# DDR16SS0_CTLPHY_WRAP_CTL_CFG_CTLCFG register map
Vendor: Texas Instruments
Registers are 32-bit, read-write, reset 0x0 unless marked. A register's access mark holds for its fields unless they carry their own. Offsets are as the file gives them; [hi:lo] are bit positions; lines under a group give offsets from that group; {n}, {i} and the like mark numbered series.

## DDR16SS0_CTLPHY_WRAP_CTL_CFG_CTLCFG (part 4 of 9)
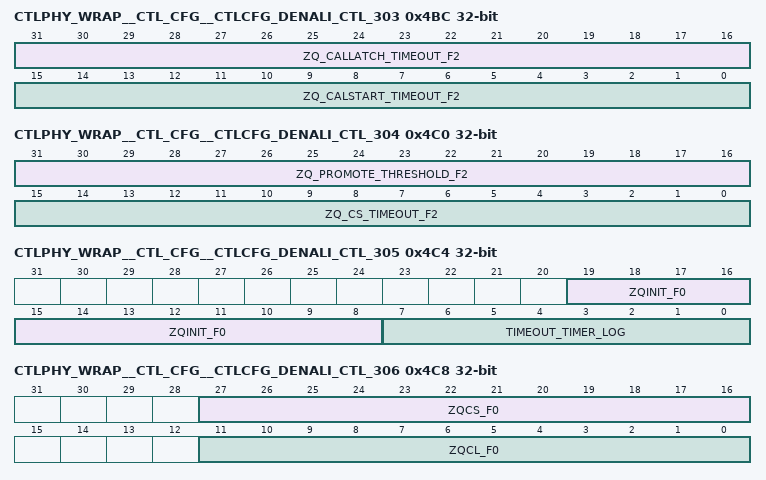
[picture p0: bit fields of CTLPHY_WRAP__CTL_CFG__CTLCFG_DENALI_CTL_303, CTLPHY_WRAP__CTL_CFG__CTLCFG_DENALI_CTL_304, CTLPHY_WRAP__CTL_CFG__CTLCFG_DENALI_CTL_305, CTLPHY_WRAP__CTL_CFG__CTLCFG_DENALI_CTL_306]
0x4BC CTLPHY_WRAP__CTL_CFG__CTLCFG_DENALI_CTL_303
  [31:16] ZQ_CALLATCH_TIMEOUT_F2 — ZQ LATCH number of long counts until the timeout is asserted. FC=2
  [15:0] ZQ_CALSTART_TIMEOUT_F2 — ZQ START number of long counts until the timeout is asserted. FC=2
0x4C0 CTLPHY_WRAP__CTL_CFG__CTLCFG_DENALI_CTL_304
  [31:16] ZQ_PROMOTE_THRESHOLD_F2 — ZQ SW promotion number of long counts until the high priority request is asserted. FC=2
  [15:0] ZQ_CS_TIMEOUT_F2 — ZQ CS number of long counts until the timeout is asserted. FC=2
0x4C4 CTLPHY_WRAP__CTL_CFG__CTLCFG_DENALI_CTL_305 access per field
  [19:8] ZQINIT_F0 rw — Number of cycles needed for a ZQINIT command. FC=0
  [7:0] TIMEOUT_TIMER_LOG ro — Reflects which timers experienced a timeout error [or had an uncleared error] when the timeout interrupt fired. Bit [0] correlates to a ZQ cal init, cs, cl, or reset FM timeout. Bit [1] correlates to the ZQ calstart FM timeout. Bit [2] correlates to the ZQ callatch FM timeout. Bit [3] correlates to the MRR temperature check FM timeout. Bit [4] correlates to the DQS oscillator FM timeout. Bit [5] correlates to the DFI update FM timeout. Bit [6] correlates to the low power interface wakeup timeout. Bit [7] correlates to the auto refresh max deficit timeout. READ-ONLY
0x4C8 CTLPHY_WRAP__CTL_CFG__CTLCFG_DENALI_CTL_306
  [27:16] ZQCS_F0 — Number of cycles needed for a ZQCS command. FC=0
  [11:0] ZQCL_F0 — Number of cycles needed for a ZQCL command. FC=0
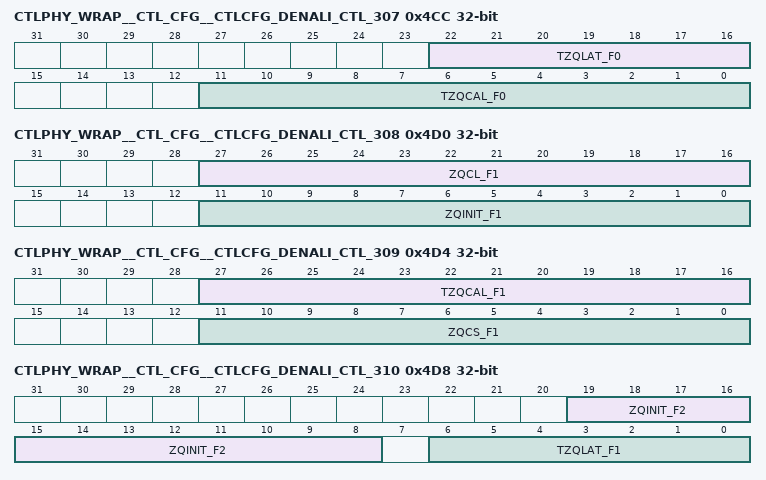
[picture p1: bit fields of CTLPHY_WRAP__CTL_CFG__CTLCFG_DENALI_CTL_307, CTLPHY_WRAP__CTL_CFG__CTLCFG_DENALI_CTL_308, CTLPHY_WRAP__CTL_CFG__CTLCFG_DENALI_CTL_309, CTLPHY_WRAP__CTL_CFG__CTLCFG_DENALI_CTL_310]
0x4CC CTLPHY_WRAP__CTL_CFG__CTLCFG_DENALI_CTL_307
  [22:16] TZQLAT_F0 — Holds the DRAM ZQLAT value in cycles. FC=0
  [11:0] TZQCAL_F0 — Holds the DRAM ZQCAL value in cycles. FC=0
0x4D0 CTLPHY_WRAP__CTL_CFG__CTLCFG_DENALI_CTL_308
  [27:16] ZQCL_F1 — Number of cycles needed for a ZQCL command. FC=1
  [11:0] ZQINIT_F1 — Number of cycles needed for a ZQINIT command. FC=1
0x4D4 CTLPHY_WRAP__CTL_CFG__CTLCFG_DENALI_CTL_309
  [27:16] TZQCAL_F1 — Holds the DRAM ZQCAL value in cycles. FC=1
  [11:0] ZQCS_F1 — Number of cycles needed for a ZQCS command. FC=1
0x4D8 CTLPHY_WRAP__CTL_CFG__CTLCFG_DENALI_CTL_310
  [19:8] ZQINIT_F2 — Number of cycles needed for a ZQINIT command. FC=2
  [6:0] TZQLAT_F1 — Holds the DRAM ZQLAT value in cycles. FC=1
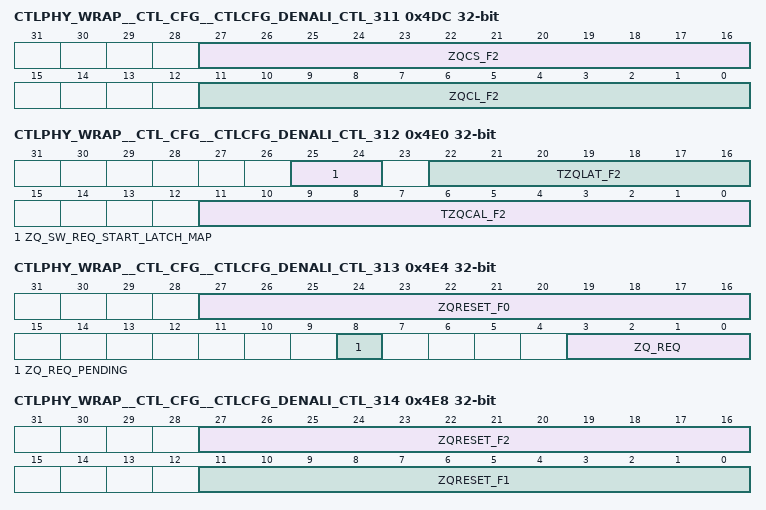
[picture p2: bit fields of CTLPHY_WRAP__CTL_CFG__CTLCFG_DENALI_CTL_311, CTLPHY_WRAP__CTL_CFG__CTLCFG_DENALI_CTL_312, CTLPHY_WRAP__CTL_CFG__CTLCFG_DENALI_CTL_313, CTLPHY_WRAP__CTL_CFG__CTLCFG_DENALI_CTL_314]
0x4DC CTLPHY_WRAP__CTL_CFG__CTLCFG_DENALI_CTL_311
  [27:16] ZQCS_F2 — Number of cycles needed for a ZQCS command. FC=2
  [11:0] ZQCL_F2 — Number of cycles needed for a ZQCL command. FC=2
0x4E0 CTLPHY_WRAP__CTL_CFG__CTLCFG_DENALI_CTL_312
  [25:24] ZQ_SW_REQ_START_LATCH_MAP — Specifies which chip selects will simultaneously receive a ZQ start or latch command once the ZQ_REQ parameter is written with a ZQ Start or ZQ Latch command.
  [22:16] TZQLAT_F2 — Holds the DRAM ZQLAT value in cycles. FC=2
  [11:0] TZQCAL_F2 — Holds the DRAM ZQCAL value in cycles. FC=2
0x4E4 CTLPHY_WRAP__CTL_CFG__CTLCFG_DENALI_CTL_313 access per field
  [27:16] ZQRESET_F0 rw — Number of cycles needed for a ZQRESET command. FC=0
  [8] ZQ_REQ_PENDING ro — Indicates that a ZQ command is currently in progress or waiting to run. Value of 1 indicates command in progress or waiting to run. When this is asserted, no writes to ZQ_REQ should occur. READ-ONLY
  [3:0] ZQ_REQ wo — User request to initiate a ZQ calibration. Program to 3 for ZQ Start, program to 4 for ZQ Initialization [ZQINIT], program to 5 for ZQ Latch, or program to 8 for ZQ Reset. Clearing to 0 will not trigger any ZQ command. This parameter should only be written when the ZQ_REQ_PENDING parameter is cleared to 0. WRITE-ONLY
0x4E8 CTLPHY_WRAP__CTL_CFG__CTLCFG_DENALI_CTL_314
  [27:16] ZQRESET_F2 — Number of cycles needed for a ZQRESET command. FC=2
  [11:0] ZQRESET_F1 — Number of cycles needed for a ZQRESET command. FC=1
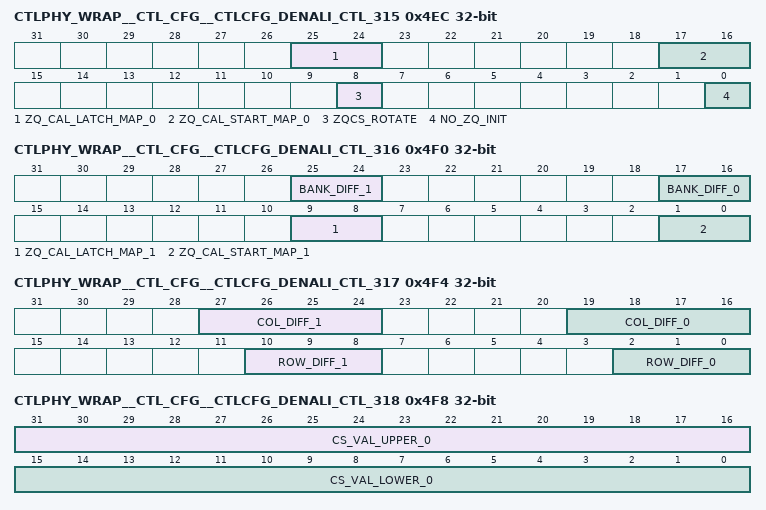
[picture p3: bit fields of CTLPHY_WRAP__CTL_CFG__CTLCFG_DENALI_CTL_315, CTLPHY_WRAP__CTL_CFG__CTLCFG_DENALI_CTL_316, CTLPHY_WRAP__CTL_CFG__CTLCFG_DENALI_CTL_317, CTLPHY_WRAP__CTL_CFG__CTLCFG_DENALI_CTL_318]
0x4EC CTLPHY_WRAP__CTL_CFG__CTLCFG_DENALI_CTL_315
  [25:24] ZQ_CAL_LATCH_MAP_0 — Defines which chip select[s] will receive ZQ calibration latch commands simultaneously on iteration 0 of the ZQ LATCH initialization and periodic command sequences. Clear to all zeros for no ZQ LATCH commands. CS=0
  [17:16] ZQ_CAL_START_MAP_0 — Defines which chip select[s] will receive ZQ calibration start commands simultaneously on iteration 0 of the ZQ START initialization and periodic command sequences. Clear to all zeros for no ZQ START commands. CS=0
  [8] ZQCS_ROTATE — For memories that perform ZQ short commands [ZQCS], selects whether a ZQCS command will calibrate just one chip select or all chip selects. When rotation is off, all chip selects will be calibrated, requiring a longer time frame, but ZQ calibration will need to be performed less frequently. Set to 1 for rotating CS. For ZQ start/latch memories, this parameter is ignored.
  [0] NO_ZQ_INIT — Disable ZQ operations during initialization. Set to 1 to disable.
0x4F0 CTLPHY_WRAP__CTL_CFG__CTLCFG_DENALI_CTL_316
  [25:24] BANK_DIFF_1 — Encoded number of banks on the DRAM[s].
  [17:16] BANK_DIFF_0 — Encoded number of banks on the DRAM[s].
  [9:8] ZQ_CAL_LATCH_MAP_1 — Defines which chip select[s] will receive ZQ calibration latch commands simultaneously on iteration 1 of the ZQ LATCH initialization and periodic command sequences. Clear to all zeros for no ZQ LATCH commands. CS=1
  [1:0] ZQ_CAL_START_MAP_1 — Defines which chip select[s] will receive ZQ calibration start commands simultaneously on iteration 1 of the ZQ START initialization and periodic command sequences. Clear to all zeros for no ZQ START commands. CS=1
0x4F4 CTLPHY_WRAP__CTL_CFG__CTLCFG_DENALI_CTL_317
  [27:24] COL_DIFF_1 — Difference between number of column pins available and number being used.
  [19:16] COL_DIFF_0 — Difference between number of column pins available and number being used.
  [10:8] ROW_DIFF_1 — Difference between number of address pins available and number being used.
  [2:0] ROW_DIFF_0 — Difference between number of address pins available and number being used.
0x4F8 CTLPHY_WRAP__CTL_CFG__CTLCFG_DENALI_CTL_318
  [31:16] CS_VAL_UPPER_0 — Upper bound address for chip select 0.
  [15:0] CS_VAL_LOWER_0 — Lower bound address for chip select 0.
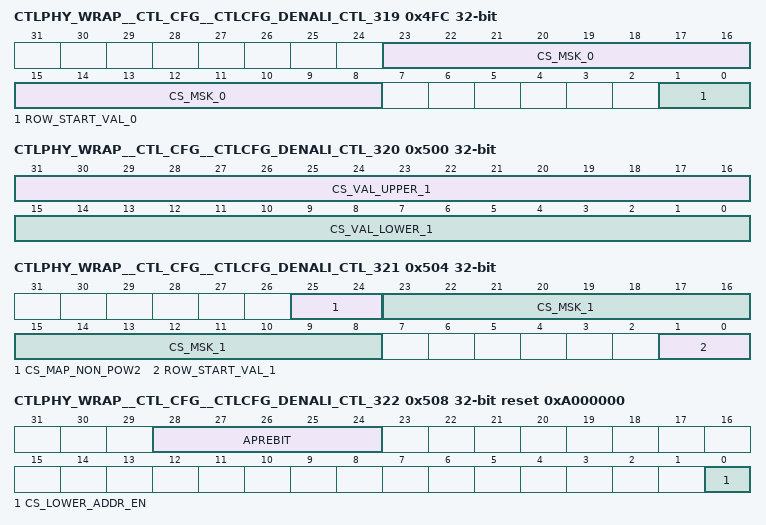
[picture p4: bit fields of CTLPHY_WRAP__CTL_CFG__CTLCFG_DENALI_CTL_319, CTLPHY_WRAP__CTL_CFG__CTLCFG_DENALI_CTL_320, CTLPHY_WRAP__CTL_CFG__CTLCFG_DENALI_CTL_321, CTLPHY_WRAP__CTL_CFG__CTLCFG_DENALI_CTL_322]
0x4FC CTLPHY_WRAP__CTL_CFG__CTLCFG_DENALI_CTL_319
  [23:8] CS_MSK_0 — Mask applied to the address decode for chip select 0.
  [1:0] ROW_START_VAL_0 — Row start value for chip select 0.
0x500 CTLPHY_WRAP__CTL_CFG__CTLCFG_DENALI_CTL_320
  [31:16] CS_VAL_UPPER_1 — Upper bound address for chip select 1.
  [15:0] CS_VAL_LOWER_1 — Lower bound address for chip select 1.
0x504 CTLPHY_WRAP__CTL_CFG__CTLCFG_DENALI_CTL_321
  [25:24] CS_MAP_NON_POW2 — Defines which chip selects are non-power-of-2 memory sizes.
  [23:8] CS_MSK_1 — Mask applied to the address decode for chip select 1.
  [1:0] ROW_START_VAL_1 — Row start value for chip select 1.
0x508 CTLPHY_WRAP__CTL_CFG__CTLCFG_DENALI_CTL_322 reset 0xA000000
  [28:24] APREBIT — Location of the auto pre-charge bit in the DRAM address.
  [0] CS_LOWER_ADDR_EN — Enables moving the CS field to lower in the address map. When set to 1, the memory address map will be changed to ROW__CS__BANK. Please refer to the limitations before setting this bit.
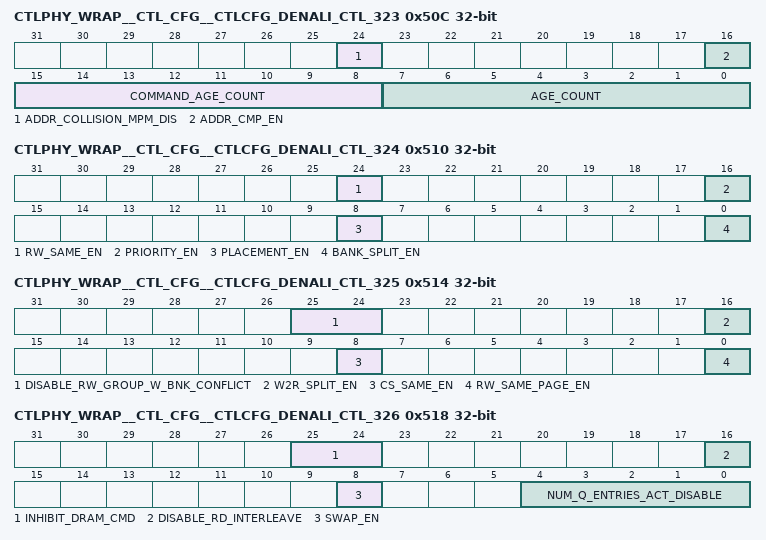
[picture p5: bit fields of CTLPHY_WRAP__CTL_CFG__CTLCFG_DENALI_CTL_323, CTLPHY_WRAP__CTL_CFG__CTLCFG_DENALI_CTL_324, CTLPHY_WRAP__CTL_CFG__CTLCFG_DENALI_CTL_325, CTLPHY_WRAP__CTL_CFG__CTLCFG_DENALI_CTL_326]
0x50C CTLPHY_WRAP__CTL_CFG__CTLCFG_DENALI_CTL_323
  [24] ADDR_COLLISION_MPM_DIS — Disable address collision detection extension using micro page mask for command queue placement and selection. Set to 1 to disable.
  [16] ADDR_CMP_EN — Enable address collision detection as a rule for command queue placement. Set to 1 to enable.
  [15:8] COMMAND_AGE_COUNT — Initial value of individual command aging counters for command aging.
  [7:0] AGE_COUNT — Initial value of master aging-rate counter for command aging.
0x510 CTLPHY_WRAP__CTL_CFG__CTLCFG_DENALI_CTL_324
  [24] RW_SAME_EN — Enable read/write grouping as a rule for command queue placement. Set to 1 to enable.
  [16] PRIORITY_EN — Enable priority as a rule for command queue placement. Set to 1 to enable.
  [8] PLACEMENT_EN — Enable placement logic for command queue. Set to 1 to enable.
  [0] BANK_SPLIT_EN — Enable bank splitting as a rule for command queue placement. Set to 1 to enable.
0x514 CTLPHY_WRAP__CTL_CFG__CTLCFG_DENALI_CTL_325
  [25:24] DISABLE_RW_GROUP_W_BNK_CONFLICT — Disables placement to read/write group when grouping creates a bank collision. Bit [0] controls placement next to bank conflict command and bit [1] controls placement 2 away from bank conflict command. Set each bit to 1 to disable.
  [16] W2R_SPLIT_EN — Enable splitting of commands to the same chip select from a write to a read command as a rule for command queue placement.
  [8] CS_SAME_EN — Enable chip select grouping when read/write grouping as a rule for command queue placement. This is only valid when the RW_SAME_EN parameter is set. Set to 1 to enable.
  [0] RW_SAME_PAGE_EN — Enable page grouping when read/write grouping as a rule for command queue placement. This is only valid when the RW_SAME_EN parameter is set. Set to 1 to enable.
0x518 CTLPHY_WRAP__CTL_CFG__CTLCFG_DENALI_CTL_326
  [25:24] INHIBIT_DRAM_CMD — Inhibit command types from being executed from the command queue. Clear to 0 to enable any command, program to 1 to inhibit read/write and bank commands, program to 2 to inhibit MRR and peripheral MRR commands, or program to 3 to inhibit MRR and read/write commands.
  [16] DISABLE_RD_INTERLEAVE — Disable read data interleaving for commands from the same port, regardless of the requestor ID.
  [8] SWAP_EN — Enable command swapping logic in execution unit. Set to 1 to enable.
  [4:0] NUM_Q_ENTRIES_ACT_DISABLE — Number of queue entries in which ACT requests will be disabled. Programming to X will disable ACT requests from the X entries lowest in the command queue.
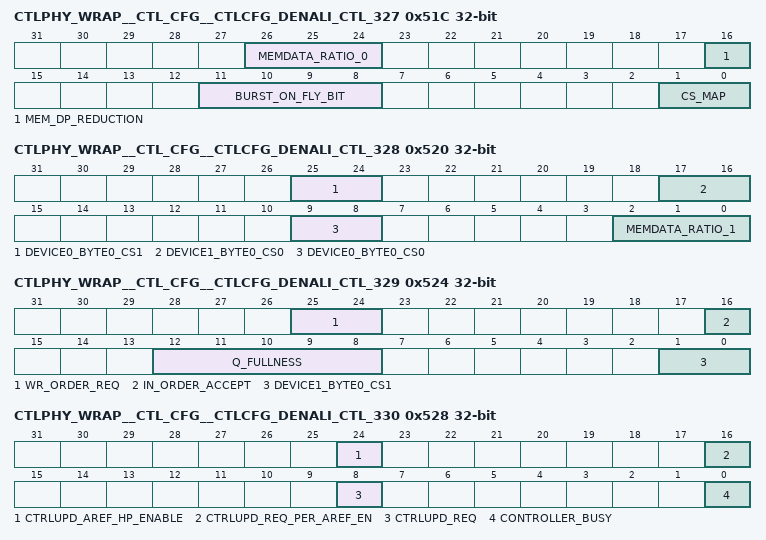
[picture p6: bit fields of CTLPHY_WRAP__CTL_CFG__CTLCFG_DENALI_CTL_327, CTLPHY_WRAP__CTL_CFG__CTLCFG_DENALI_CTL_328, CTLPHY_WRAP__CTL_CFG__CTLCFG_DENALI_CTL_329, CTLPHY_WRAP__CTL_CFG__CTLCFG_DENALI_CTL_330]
0x51C CTLPHY_WRAP__CTL_CFG__CTLCFG_DENALI_CTL_327
  [26:24] MEMDATA_RATIO_0 — Defines the ratio of the DRAM device size on chip select 0 to the memory data width. Program with the log2 ratio of the memory data width to the device data width. CS=0
  [16] MEM_DP_REDUCTION — Enable the half datapath feature of the controller. Set to 1 to enable.
  [11:8] BURST_ON_FLY_BIT — Identifies the burst-on-fly bit in the memory mode registers.
  [1:0] CS_MAP — Defines which chip selects are active.
0x520 CTLPHY_WRAP__CTL_CFG__CTLCFG_DENALI_CTL_328
  [25:24] DEVICE0_BYTE0_CS1 — Defines the byte location of byte0 in the memory datapath for device 0 on chip 1. Used for MRRs to identify where data will be returned. DEV=0
  [17:16] DEVICE1_BYTE0_CS0 — Defines the byte location of byte0 in the memory datapath for device 1 on chip 0. Used for MRRs to identify where data will be returned. DEV=1
  [9:8] DEVICE0_BYTE0_CS0 — Defines the byte location of byte0 in the memory datapath for device 0 on chip 0. Used for MRRs to identify where data will be returned. DEV=0
  [2:0] MEMDATA_RATIO_1 — Defines the ratio of the DRAM device size on chip select 1 to the memory data width. Program with the log2 ratio of the memory data width to the device data width. CS=1
0x524 CTLPHY_WRAP__CTL_CFG__CTLCFG_DENALI_CTL_329
  [25:24] WR_ORDER_REQ — Determines if the controller can re-order write commands from the same source ID and/or the same port. Bit [0] controls source ID usage and bit [1] controls port ID usage. Set each bit to 1 to enable usage in placement logic.
  [16] IN_ORDER_ACCEPT — Forces the controller to accept commands in the order in which they are placed in the command queue.
  [12:8] Q_FULLNESS — Quantity that determines when the command queue almost full signal will assert [q_almost_full]. When cleared to 0, the q_almost_full signal will be driven to 0 irrespective of number of entries in the command queue.
  [1:0] DEVICE1_BYTE0_CS1 — Defines the byte location of byte0 in the memory datapath for device 1 on chip 1. Used for MRRs to identify where data will be returned. DEV=1
0x528 CTLPHY_WRAP__CTL_CFG__CTLCFG_DENALI_CTL_330 access per field
  [24] CTRLUPD_AREF_HP_ENABLE rw — Enable an automatic controller-initiated update [dfi_ctrlupd_req] after every high priority refresh when executing as a subtask request. Set to 1 to enable.
  [16] CTRLUPD_REQ_PER_AREF_EN rw — Enable an automatic controller-initiated update [dfi_ctrlupd_req] after every refresh. Set to 1 to enable.
  [8] CTRLUPD_REQ wo — Assert the DFI controller-initiated update request signal dfi_ctrlupd_req. Set to 1 to trigger. WRITE-ONLY
  [0] CONTROLLER_BUSY ro — Indicator that the controller is processing a command. Evaluates all ports for outstanding transactions. Value of 1 indicates controller busy. READ-ONLY
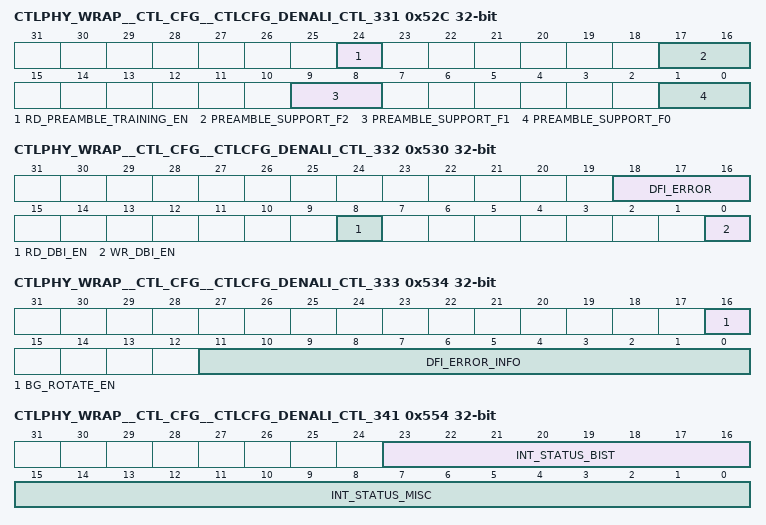
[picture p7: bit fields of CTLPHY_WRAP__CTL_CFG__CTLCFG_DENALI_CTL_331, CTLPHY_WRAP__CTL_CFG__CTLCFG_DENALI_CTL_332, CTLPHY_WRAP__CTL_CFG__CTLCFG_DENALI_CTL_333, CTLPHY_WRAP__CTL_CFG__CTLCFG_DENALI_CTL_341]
0x52C CTLPHY_WRAP__CTL_CFG__CTLCFG_DENALI_CTL_331
  [24] RD_PREAMBLE_TRAINING_EN — Enable read preamble training during gate training. Set to 1 to enable.
  [17:16] PREAMBLE_SUPPORT_F2 — Selection the preamble for read and write burst transfers. FC=2
  [9:8] PREAMBLE_SUPPORT_F1 — Selection the preamble for read and write burst transfers. FC=1
  [1:0] PREAMBLE_SUPPORT_F0 — Selection the preamble for read and write burst transfers. FC=0
0x530 CTLPHY_WRAP__CTL_CFG__CTLCFG_DENALI_CTL_332 access per field
  [18:16] DFI_ERROR ro — Indicates that the DFI error flag has been asserted. READ-ONLY
  [8] RD_DBI_EN rw — Enables controller support of DRAM DBI feature for read data with DDR4 devices. Set to 1 to enable.
  [0] WR_DBI_EN rw — Enables controller support of DRAM DBI feature for write data with DDR4 devices. Set to 1 to enable.
0x534 CTLPHY_WRAP__CTL_CFG__CTLCFG_DENALI_CTL_333 access per field
  [16] BG_ROTATE_EN rw — Enable bank group rotation. Set to 1 to enable.
  [11:0] DFI_ERROR_INFO ro — Holds the encoded DFI error type associated with the DFI_ERROR parameter assertion. READ-ONLY
0x538 CTLPHY_WRAP__CTL_CFG__CTLCFG_DENALI_CTL_334 ro
  [31:0] INT_STATUS_MASTER — Master status reporting register for interrupt status groups. READ-ONLY
0x53C CTLPHY_WRAP__CTL_CFG__CTLCFG_DENALI_CTL_335
  [31:0] INT_MASK_MASTER — Master mask register for interrupt status groups. WRITE-ONLY
0x540 CTLPHY_WRAP__CTL_CFG__CTLCFG_DENALI_CTL_336 ro
  [31:0] INT_STATUS_TIMEOUT — Status of interrupts in the controller related to Timeout monitors. READ-ONLY
0x544 CTLPHY_WRAP__CTL_CFG__CTLCFG_DENALI_CTL_337 ro
  [31:16] INT_STATUS_LOWPOWER — Status of interrupts in the controller related to Low Power. READ-ONLY
0x548 CTLPHY_WRAP__CTL_CFG__CTLCFG_DENALI_CTL_338 access not given reset not defined
0x54C CTLPHY_WRAP__CTL_CFG__CTLCFG_DENALI_CTL_339 ro
  [31:0] INT_STATUS_TRAINING — Status of interrupts in the controller related to Training/Calibration. READ-ONLY
0x550 CTLPHY_WRAP__CTL_CFG__CTLCFG_DENALI_CTL_340 ro
  [31:0] INT_STATUS_USERIF — Status of interrupts in the controller related to ASIC to Controller Interface. READ-ONLY
0x554 CTLPHY_WRAP__CTL_CFG__CTLCFG_DENALI_CTL_341 ro
  [23:16] INT_STATUS_BIST — Status of interrupts in the controller related to BIST. READ-ONLY
  [15:0] INT_STATUS_MISC — Status of interrupts in the controller related to Miscellaneous features. READ-ONLY
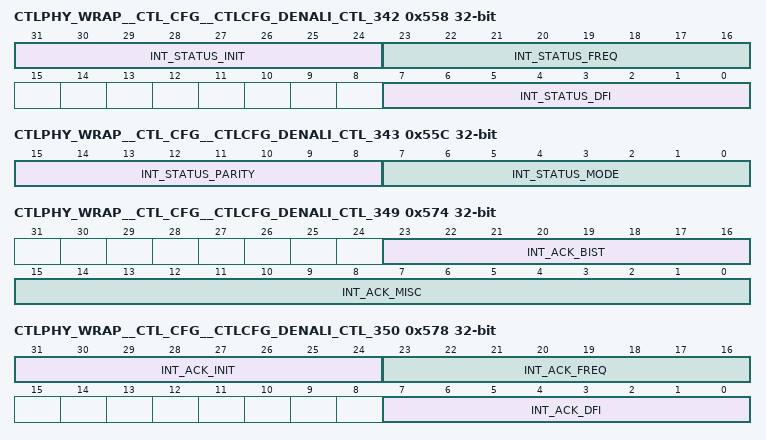
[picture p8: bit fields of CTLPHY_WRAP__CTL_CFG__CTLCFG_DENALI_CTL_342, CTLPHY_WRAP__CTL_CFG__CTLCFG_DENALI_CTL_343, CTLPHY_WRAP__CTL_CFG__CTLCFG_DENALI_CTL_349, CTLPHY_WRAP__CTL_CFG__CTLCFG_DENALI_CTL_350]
0x558 CTLPHY_WRAP__CTL_CFG__CTLCFG_DENALI_CTL_342 ro
  [31:24] INT_STATUS_INIT — Status of interrupts in the controller related to Initialization. READ-ONLY
  [23:16] INT_STATUS_FREQ — Status of interrupts in the controller related to Frequency Scaling. READ-ONLY
  [7:0] INT_STATUS_DFI — Status of interrupts in the controller related to DFI. READ-ONLY
0x55C CTLPHY_WRAP__CTL_CFG__CTLCFG_DENALI_CTL_343 ro
  [15:8] INT_STATUS_PARITY — Status of interrupts in the controller related to Parity. READ-ONLY
  [7:0] INT_STATUS_MODE — Status of interrupts in the controller related to Memory Mode Settings. READ-ONLY
0x560 CTLPHY_WRAP__CTL_CFG__CTLCFG_DENALI_CTL_344 wo
  [31:0] INT_ACK_TIMEOUT — Clear status of the INT_STATUS_TIMEOUT parameter. WRITE-ONLY
0x564 CTLPHY_WRAP__CTL_CFG__CTLCFG_DENALI_CTL_345 wo
  [31:16] INT_ACK_LOWPOWER — Clear status of the INT_STATUS_LOWPOWER parameter. WRITE-ONLY
0x568 CTLPHY_WRAP__CTL_CFG__CTLCFG_DENALI_CTL_346 access not given reset not defined
0x56C CTLPHY_WRAP__CTL_CFG__CTLCFG_DENALI_CTL_347 wo
  [31:0] INT_ACK_TRAINING — Clear status of the INT_STATUS_TRAINING parameter. WRITE-ONLY
0x570 CTLPHY_WRAP__CTL_CFG__CTLCFG_DENALI_CTL_348 wo
  [31:0] INT_ACK_USERIF — Clear status of the INT_STATUS_USERIF parameter. WRITE-ONLY
0x574 CTLPHY_WRAP__CTL_CFG__CTLCFG_DENALI_CTL_349 wo
  [23:16] INT_ACK_BIST — Clear status of the INT_STATUS_BIST parameter. WRITE-ONLY
  [15:0] INT_ACK_MISC — Clear status of the INT_STATUS_MISC parameter. WRITE-ONLY
0x578 CTLPHY_WRAP__CTL_CFG__CTLCFG_DENALI_CTL_350 wo
  [31:24] INT_ACK_INIT — Clear status of the INT_STATUS_INIT parameter. WRITE-ONLY
  [23:16] INT_ACK_FREQ — Clear status of the INT_STATUS_FREQ parameter. WRITE-ONLY
  [7:0] INT_ACK_DFI — Clear status of the INT_STATUS_DFI parameter. WRITE-ONLY
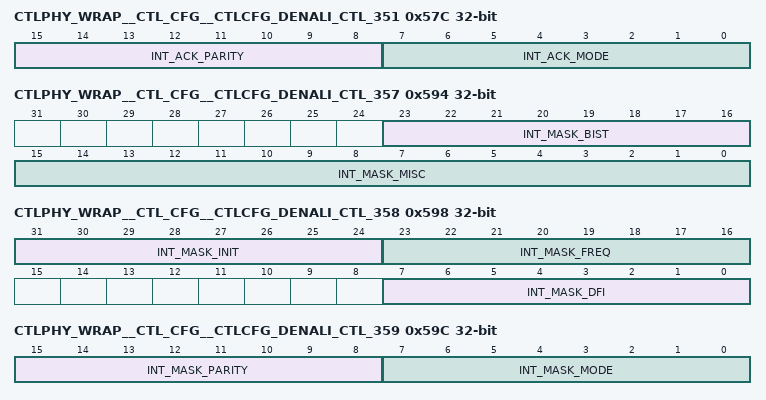
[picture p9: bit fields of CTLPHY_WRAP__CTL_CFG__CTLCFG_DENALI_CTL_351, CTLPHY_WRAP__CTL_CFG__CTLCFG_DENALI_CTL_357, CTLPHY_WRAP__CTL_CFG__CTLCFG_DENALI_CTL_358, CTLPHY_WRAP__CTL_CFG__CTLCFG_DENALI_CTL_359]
0x57C CTLPHY_WRAP__CTL_CFG__CTLCFG_DENALI_CTL_351 wo
  [15:8] INT_ACK_PARITY — Clear status of the INT_STATUS_PARITY parameter. WRITE-ONLY
  [7:0] INT_ACK_MODE — Clear status of the INT_STATUS_MODE parameter. WRITE-ONLY
0x580 CTLPHY_WRAP__CTL_CFG__CTLCFG_DENALI_CTL_352
  [31:0] INT_MASK_TIMEOUT — Mask for the controller_int signal from the INT_MASK_TIMEOUT parameter
0x584 CTLPHY_WRAP__CTL_CFG__CTLCFG_DENALI_CTL_353
  [31:16] INT_MASK_LOWPOWER — Mask for the controller_int signal from the INT_MASK_LOWPOWER parameter
0x588 CTLPHY_WRAP__CTL_CFG__CTLCFG_DENALI_CTL_354 access not given reset not defined
0x58C CTLPHY_WRAP__CTL_CFG__CTLCFG_DENALI_CTL_355
  [31:0] INT_MASK_TRAINING — Mask for the controller_int signal from the INT_MASK_TRAINING parameter
0x590 CTLPHY_WRAP__CTL_CFG__CTLCFG_DENALI_CTL_356
  [31:0] INT_MASK_USERIF — Mask for the controller_int signal from the INT_MASK_USERIF parameter
0x594 CTLPHY_WRAP__CTL_CFG__CTLCFG_DENALI_CTL_357
  [23:16] INT_MASK_BIST — Mask for the controller_int signal from the INT_MASK_BIST parameter
  [15:0] INT_MASK_MISC — Mask for the controller_int signal from the INT_MASK_MISC parameter
0x598 CTLPHY_WRAP__CTL_CFG__CTLCFG_DENALI_CTL_358
  [31:24] INT_MASK_INIT — Mask for the controller_int signal from the INT_MASK_INIT parameter
  [23:16] INT_MASK_FREQ — Mask for the controller_int signal from the INT_MASK_FREQ parameter
  [7:0] INT_MASK_DFI — Mask for the controller_int signal from the INT_MASK_DFI parameter
0x59C CTLPHY_WRAP__CTL_CFG__CTLCFG_DENALI_CTL_359
  [15:8] INT_MASK_PARITY — Mask for the controller_int signal from the INT_MASK_PARITY parameter
  [7:0] INT_MASK_MODE — Mask for the controller_int signal from the INT_MASK_MODE parameter
0x5A0 CTLPHY_WRAP__CTL_CFG__CTLCFG_DENALI_CTL_360 ro
  [31:0] OUT_OF_RANGE_ADDR_0 — Address of command that caused an out-of-range interrupt. READ-ONLY
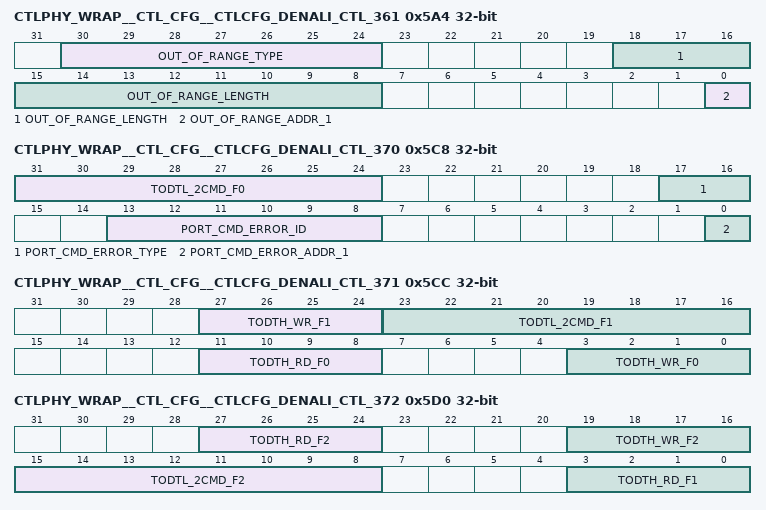
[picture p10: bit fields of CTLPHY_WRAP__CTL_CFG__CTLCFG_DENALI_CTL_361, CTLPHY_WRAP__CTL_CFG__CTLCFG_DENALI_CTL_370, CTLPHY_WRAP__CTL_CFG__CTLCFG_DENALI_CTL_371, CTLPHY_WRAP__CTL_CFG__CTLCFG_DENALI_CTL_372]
0x5A4 CTLPHY_WRAP__CTL_CFG__CTLCFG_DENALI_CTL_361 ro
  [30:24] OUT_OF_RANGE_TYPE — Type of command that caused an out-of-range interrupt. READ-ONLY
  [18:8] OUT_OF_RANGE_LENGTH — Length of command that caused an out-of-range interrupt. READ-ONLY
  [0] OUT_OF_RANGE_ADDR_1 — Address of command that caused an out-of-range interrupt. READ-ONLY
0x5A8 CTLPHY_WRAP__CTL_CFG__CTLCFG_DENALI_CTL_362 ro
  [5:0] OUT_OF_RANGE_SOURCE_ID — Source ID of command that caused an out-of-range interrupt. READ-ONLY
0x5AC CTLPHY_WRAP__CTL_CFG__CTLCFG_DENALI_CTL_363 ro
  [31:0] BIST_EXP_DATA_0 — Expected data on BIST error. READ-ONLY
0x5B0 CTLPHY_WRAP__CTL_CFG__CTLCFG_DENALI_CTL_364 ro
  [31:0] BIST_EXP_DATA_1 — Expected data on BIST error. READ-ONLY
0x5B4 CTLPHY_WRAP__CTL_CFG__CTLCFG_DENALI_CTL_365 ro
  [31:0] BIST_FAIL_DATA_0 — Actual data on BIST error. READ-ONLY
0x5B8 CTLPHY_WRAP__CTL_CFG__CTLCFG_DENALI_CTL_366 ro
  [31:0] BIST_FAIL_DATA_1 — Actual data on BIST error. READ-ONLY
0x5BC CTLPHY_WRAP__CTL_CFG__CTLCFG_DENALI_CTL_367 ro
  [31:0] BIST_FAIL_ADDR_0 — Address of BIST error. READ-ONLY
0x5C0 CTLPHY_WRAP__CTL_CFG__CTLCFG_DENALI_CTL_368 ro
  [0] BIST_FAIL_ADDR_1 — Address of BIST error. READ-ONLY
0x5C4 CTLPHY_WRAP__CTL_CFG__CTLCFG_DENALI_CTL_369 ro
  [31:0] PORT_CMD_ERROR_ADDR_0 — Address of command that caused the PORT command error. READ-ONLY
0x5C8 CTLPHY_WRAP__CTL_CFG__CTLCFG_DENALI_CTL_370 access per field
  [31:24] TODTL_2CMD_F0 rw — Defines the DRAM delay from an ODT de-assertion to the next non-write, non-read command. FC=0
  [17:16] PORT_CMD_ERROR_TYPE ro — Type of error and access type that caused the PORT command error. READ-ONLY
  [13:8] PORT_CMD_ERROR_ID ro — Source ID of command that caused the PORT command error. READ-ONLY
  [0] PORT_CMD_ERROR_ADDR_1 ro — Address of command that caused the PORT command error. READ-ONLY
0x5CC CTLPHY_WRAP__CTL_CFG__CTLCFG_DENALI_CTL_371
  [27:24] TODTH_WR_F1 — Defines the DRAM minimum ODT high time after an ODT assertion for a write command. FC=1
  [23:16] TODTL_2CMD_F1 — Defines the DRAM delay from an ODT de-assertion to the next non-write, non-read command. FC=1
  [11:8] TODTH_RD_F0 — Defines the DRAM minimum ODT high time after an ODT assertion for a read command. FC=0
  [3:0] TODTH_WR_F0 — Defines the DRAM minimum ODT high time after an ODT assertion for a write command. FC=0
0x5D0 CTLPHY_WRAP__CTL_CFG__CTLCFG_DENALI_CTL_372
  [27:24] TODTH_RD_F2 — Defines the DRAM minimum ODT high time after an ODT assertion for a read command. FC=2
  [19:16] TODTH_WR_F2 — Defines the DRAM minimum ODT high time after an ODT assertion for a write command. FC=2
  [15:8] TODTL_2CMD_F2 — Defines the DRAM delay from an ODT de-assertion to the next non-write, non-read command. FC=2
  [3:0] TODTH_RD_F1 — Defines the DRAM minimum ODT high time after an ODT assertion for a read command. FC=1
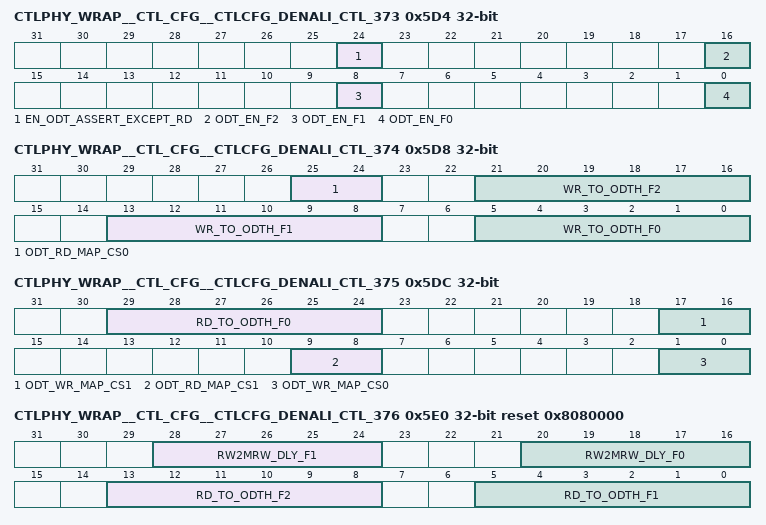
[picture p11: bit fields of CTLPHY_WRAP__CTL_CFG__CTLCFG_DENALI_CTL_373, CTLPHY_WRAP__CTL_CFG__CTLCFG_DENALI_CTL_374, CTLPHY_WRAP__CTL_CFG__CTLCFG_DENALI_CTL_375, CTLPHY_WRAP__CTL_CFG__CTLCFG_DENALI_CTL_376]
0x5D4 CTLPHY_WRAP__CTL_CFG__CTLCFG_DENALI_CTL_373
  [24] EN_ODT_ASSERT_EXCEPT_RD — Enable controller to assert ODT at all times except during reads. Assumes single ODT pin connected. Set to 1 to enable.
  [16] ODT_EN_F2 — Enable support of DRAM ODT. When enabled, controller will assert and de-assert ODT output to DRAM as needed. FC=2
  [8] ODT_EN_F1 — Enable support of DRAM ODT. When enabled, controller will assert and de-assert ODT output to DRAM as needed. FC=1
  [0] ODT_EN_F0 — Enable support of DRAM ODT. When enabled, controller will assert and de-assert ODT output to DRAM as needed. FC=0
0x5D8 CTLPHY_WRAP__CTL_CFG__CTLCFG_DENALI_CTL_374
  [25:24] ODT_RD_MAP_CS0 — Determines which chip[s] will have termination when a read occurs. Set bit X to enable termination on csX when a read is performed. CS=0
  [21:16] WR_TO_ODTH_F2 — Defines the delay from a write command to ODT assertion. FC=2
  [13:8] WR_TO_ODTH_F1 — Defines the delay from a write command to ODT assertion. FC=1
  [5:0] WR_TO_ODTH_F0 — Defines the delay from a write command to ODT assertion. FC=0
0x5DC CTLPHY_WRAP__CTL_CFG__CTLCFG_DENALI_CTL_375
  [29:24] RD_TO_ODTH_F0 — Defines the delay from a read command to ODT assertion. FC=0
  [17:16] ODT_WR_MAP_CS1 — Determines which chip[s] will have termination when a write occurs. Set bit X to enable termination on csX when a write is performed. CS=1
  [9:8] ODT_RD_MAP_CS1 — Determines which chip[s] will have termination when a read occurs. Set bit X to enable termination on csX when a read is performed. CS=1
  [1:0] ODT_WR_MAP_CS0 — Determines which chip[s] will have termination when a write occurs. Set bit X to enable termination on csX when a write is performed. CS=0
0x5E0 CTLPHY_WRAP__CTL_CFG__CTLCFG_DENALI_CTL_376 reset 0x8080000
  [28:24] RW2MRW_DLY_F1 — Additional delay to insert between read or write and mode_reg_write. Allowed programming dependent on memory system. FC=1
  [20:16] RW2MRW_DLY_F0 — Additional delay to insert between read or write and mode_reg_write. Allowed programming dependent on memory system. FC=0
  [13:8] RD_TO_ODTH_F2 — Defines the delay from a read command to ODT assertion. FC=2
  [5:0] RD_TO_ODTH_F1 — Defines the delay from a read command to ODT assertion. FC=1
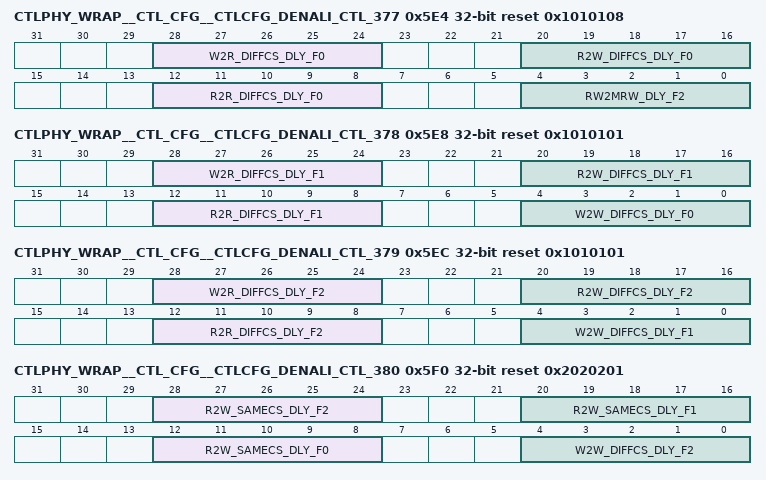
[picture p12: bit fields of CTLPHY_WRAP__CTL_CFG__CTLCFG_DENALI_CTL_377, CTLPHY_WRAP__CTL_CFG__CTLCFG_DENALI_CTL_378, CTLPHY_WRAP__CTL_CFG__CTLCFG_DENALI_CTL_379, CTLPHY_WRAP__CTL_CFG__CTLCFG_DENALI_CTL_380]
0x5E4 CTLPHY_WRAP__CTL_CFG__CTLCFG_DENALI_CTL_377 reset 0x1010108
  [28:24] W2R_DIFFCS_DLY_F0 — Additional delay to insert between writes and reads to different chip selects. Allowed programming dependent on memory system. FC=0
  [20:16] R2W_DIFFCS_DLY_F0 — Additional delay to insert between reads and writes to different chip selects. Program to a non-zero value. FC=0
  [12:8] R2R_DIFFCS_DLY_F0 — Additional delay to insert between reads to different chip selects. Program to a non-zero value. FC=0
  [4:0] RW2MRW_DLY_F2 — Additional delay to insert between read or write and mode_reg_write. Allowed programming dependent on memory system. FC=2
0x5E8 CTLPHY_WRAP__CTL_CFG__CTLCFG_DENALI_CTL_378 reset 0x1010101
  [28:24] W2R_DIFFCS_DLY_F1 — Additional delay to insert between writes and reads to different chip selects. Allowed programming dependent on memory system. FC=1
  [20:16] R2W_DIFFCS_DLY_F1 — Additional delay to insert between reads and writes to different chip selects. Program to a non-zero value. FC=1
  [12:8] R2R_DIFFCS_DLY_F1 — Additional delay to insert between reads to different chip selects. Program to a non-zero value. FC=1
  [4:0] W2W_DIFFCS_DLY_F0 — Additional delay to insert between writes to different chip selects. Program to a non-zero value. FC=0
0x5EC CTLPHY_WRAP__CTL_CFG__CTLCFG_DENALI_CTL_379 reset 0x1010101
  [28:24] W2R_DIFFCS_DLY_F2 — Additional delay to insert between writes and reads to different chip selects. Allowed programming dependent on memory system. FC=2
  [20:16] R2W_DIFFCS_DLY_F2 — Additional delay to insert between reads and writes to different chip selects. Program to a non-zero value. FC=2
  [12:8] R2R_DIFFCS_DLY_F2 — Additional delay to insert between reads to different chip selects. Program to a non-zero value. FC=2
  [4:0] W2W_DIFFCS_DLY_F1 — Additional delay to insert between writes to different chip selects. Program to a non-zero value. FC=1
0x5F0 CTLPHY_WRAP__CTL_CFG__CTLCFG_DENALI_CTL_380 reset 0x2020201
  [28:24] R2W_SAMECS_DLY_F2 — Additional delay to insert between reads and writes to the same chip select. Program to a non-zero value. FC=2
  [20:16] R2W_SAMECS_DLY_F1 — Additional delay to insert between reads and writes to the same chip select. Program to a non-zero value. FC=1
  [12:8] R2W_SAMECS_DLY_F0 — Additional delay to insert between reads and writes to the same chip select. Program to a non-zero value. FC=0
  [4:0] W2W_DIFFCS_DLY_F2 — Additional delay to insert between writes to different chip selects. Program to a non-zero value. FC=2
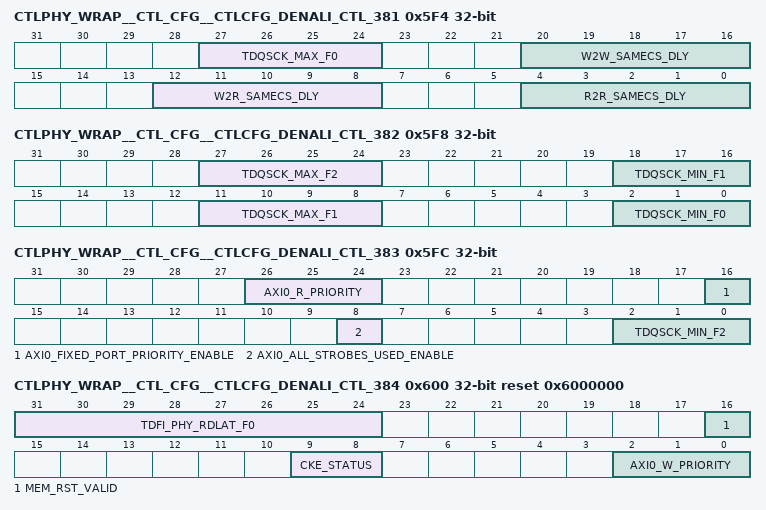
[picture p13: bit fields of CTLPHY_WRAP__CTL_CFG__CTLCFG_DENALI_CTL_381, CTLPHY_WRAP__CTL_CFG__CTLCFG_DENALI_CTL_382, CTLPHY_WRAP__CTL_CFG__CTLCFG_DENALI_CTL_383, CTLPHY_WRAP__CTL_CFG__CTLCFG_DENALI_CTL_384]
0x5F4 CTLPHY_WRAP__CTL_CFG__CTLCFG_DENALI_CTL_381
  [27:24] TDQSCK_MAX_F0 — Additional delay needed for tDQSCK. FC=0
  [20:16] W2W_SAMECS_DLY — Additional delay to insert between two writes to the same chip select. Any value including 0 supported.
  [12:8] W2R_SAMECS_DLY — Additional delay to insert between writes and reads to the same chip select.
  [4:0] R2R_SAMECS_DLY — Additional delay to insert between two reads to the same chip select. Any value including 0 supported.
0x5F8 CTLPHY_WRAP__CTL_CFG__CTLCFG_DENALI_CTL_382
  [27:24] TDQSCK_MAX_F2 — Additional delay needed for tDQSCK. FC=2
  [18:16] TDQSCK_MIN_F1 — Additional delay needed for tDQSCK. FC=1
  [11:8] TDQSCK_MAX_F1 — Additional delay needed for tDQSCK. FC=1
  [2:0] TDQSCK_MIN_F0 — Additional delay needed for tDQSCK. FC=0
0x5FC CTLPHY_WRAP__CTL_CFG__CTLCFG_DENALI_CTL_383
  [26:24] AXI0_R_PRIORITY — Priority of read commands from AXI port 0. 0 is the highest priority. This may only be changed before initialization begins or when the controller is quiescent, there is no data in the port FIFOs, and the AXI0_FIXED_PORT_PRIORITY_ENABLE parameter is low.
  [16] AXI0_FIXED_PORT_PRIORITY_ENABLE — Defines the priority control for AXI port 0 as per-port or per-command. Set to 1 for per-port with priority defined through the AXI.0._R_PRIORITY and AXI.0._W_PRIORITY parameters. Clear to 0 for per-command.
  [8] AXI0_ALL_STROBES_USED_ENABLE — Enables use of the AWALLSTRB signal for AXI port 0. Set to 1 to enable.
  [2:0] TDQSCK_MIN_F2 — Additional delay needed for tDQSCK. FC=2
0x600 CTLPHY_WRAP__CTL_CFG__CTLCFG_DENALI_CTL_384 access per field reset 0x6000000
  [31:24] TDFI_PHY_RDLAT_F0 rw — Defines the DFI tPHY_RDLAT timing parameter [in DFI PHY clocks], the maximum cycles between a dfi_rddata_en assertion and a dfi_rddata_valid assertion. FC=0
  [16] MEM_RST_VALID ro — Register access to mem_rst_valid signal. READ-ONLY
  [9:8] CKE_STATUS ro — Register access to cke_status signal. READ-ONLY
  [2:0] AXI0_W_PRIORITY rw — Priority of write commands from AXI port 0. 0 is the highest priority. This may only be changed before initialization begins or when the controller is quiescent, there is no data in the port FIFOs, and the AXI0_FIXED_PORT_PRIORITY_ENABLE parameter is low.
0x604 CTLPHY_WRAP__CTL_CFG__CTLCFG_DENALI_CTL_385
  [20:0] TDFI_CTRLUPD_MAX_F0 — Defines the DFI tCTRLUPD_MAX timing parameter [in DFI clocks], the maximum cycles that dfi_ctrlupd_req can be asserted. If programmed to a non-zero, a timing violation will cause an interrupt and bit [0] set in the UPDATE_ERROR_STATUS parameter. FC=0
{0x0+4i} CTLPHY_WRAP__CTL_CFG__CTLCFG_DENALI_CTL_{i} (i=386..389)
  [31:0] TDFI_PHYUPD_TYPE{i-386}_F0 — Defines the DFI tPHYUPD_TYPE{i-386} timing parameter [in DFI clocks], the maximum cycles that dfi_phyupd_req can assert after dfi_phyupd_ack for dfi_phyupd_type {i-386}. If programmed to a non-zero, a timing violation will cause an interrupt and bit [{i-385}] set in the UPDATE_ERROR_STATUS parameter. FC=0
0x618 CTLPHY_WRAP__CTL_CFG__CTLCFG_DENALI_CTL_390
  [22:0] TDFI_PHYUPD_RESP_F0 — Defines the DFI tPHYUPD_RESP timing parameter [in DFI clocks], the maximum cycles between a dfi_phyupd_req assertion and a dfi_phyupd_ack assertion. If programmed to a non-zero, a timing violation will cause an interrupt and bit [5] set in the UPDATE_ERROR_STATUS parameter. FC=0
0x61C CTLPHY_WRAP__CTL_CFG__CTLCFG_DENALI_CTL_391
  [31:0] TDFI_CTRLUPD_INTERVAL_F0 — Defines the DFI tCTRLUPD_INTERVAL timing parameter [in DFI clocks], the maximum cycles between dfi_ctrlupd_req assertions. If programmed to a non-zero, a timing violation will cause an interrupt and bit [6] set in the UPDATE_ERROR_STATUS parameter. FC=0
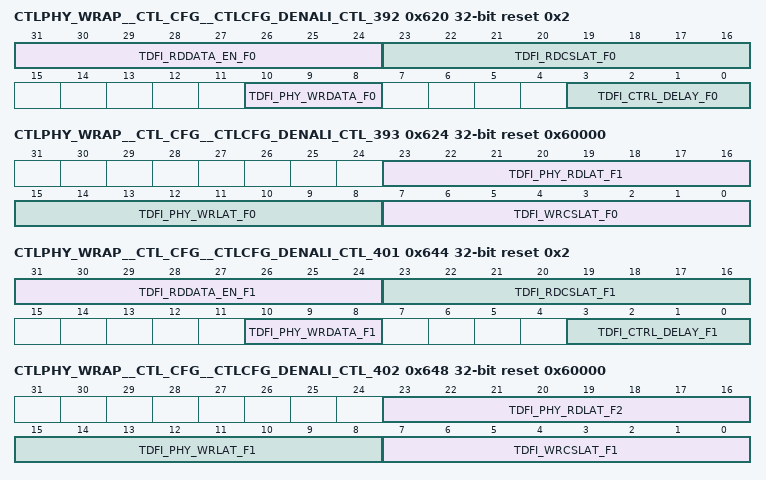
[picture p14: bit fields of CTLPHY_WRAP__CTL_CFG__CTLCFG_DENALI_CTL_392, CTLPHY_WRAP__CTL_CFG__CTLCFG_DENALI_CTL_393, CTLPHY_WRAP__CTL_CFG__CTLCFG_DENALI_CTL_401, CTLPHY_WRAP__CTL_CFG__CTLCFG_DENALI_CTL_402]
0x620 CTLPHY_WRAP__CTL_CFG__CTLCFG_DENALI_CTL_392 reset 0x2
  [31:24] TDFI_RDDATA_EN_F0 — DFI tRDDATA_EN timing parameter. This is the number of DFI data phases between a read command and the first assertion of dfi_rddata_en_pN. FC=0
  [23:16] TDFI_RDCSLAT_F0 — Defines the DFI tPHY_RDCSLAT timing parameter [in DFI PHY clocks], the maximum cycles between a read command and a dfi_rddata_cs_n assertion. FC=0
  [10:8] TDFI_PHY_WRDATA_F0 — Defines the DFI tPHY_WRDATA timing parameter [in DFI PHY clocks], the maximum cycles between a dfi_wrdata_en assertion and a dfi_wrdata signal. FC=0
  [3:0] TDFI_CTRL_DELAY_F0 — Defines the DFI tCTRL_DELAY timing parameter [in DFI clocks], the delay between a DFI command change and a memory command. FC=0
0x624 CTLPHY_WRAP__CTL_CFG__CTLCFG_DENALI_CTL_393 reset 0x60000
  [23:16] TDFI_PHY_RDLAT_F1 — Defines the DFI tPHY_RDLAT timing parameter [in DFI PHY clocks], the maximum cycles between a dfi_rddata_en assertion and a dfi_rddata_valid assertion. FC=1
  [15:8] TDFI_PHY_WRLAT_F0 — DFI tPHY_WRLAT timing parameter. This is the number of DFI data phases between a write command and the first assertion of dfi_wrdata_en_pN. FC=0
  [7:0] TDFI_WRCSLAT_F0 — Defines the DFI tPHY_WRCSLAT timing parameter [in DFI PHY clocks], the maximum cycles between a write command and a dfi_wrdata_cs_n assertion. FC=0
0x628 CTLPHY_WRAP__CTL_CFG__CTLCFG_DENALI_CTL_394
  [20:0] TDFI_CTRLUPD_MAX_F1 — Defines the DFI tCTRLUPD_MAX timing parameter [in DFI clocks], the maximum cycles that dfi_ctrlupd_req can be asserted. If programmed to a non-zero, a timing violation will cause an interrupt and bit [0] set in the UPDATE_ERROR_STATUS parameter. FC=1
{0x0+4i} CTLPHY_WRAP__CTL_CFG__CTLCFG_DENALI_CTL_{i} (i=395..398)
  [31:0] TDFI_PHYUPD_TYPE{i-395}_F1 — Defines the DFI tPHYUPD_TYPE{i-395} timing parameter [in DFI clocks], the maximum cycles that dfi_phyupd_req can assert after dfi_phyupd_ack for dfi_phyupd_type {i-395}. If programmed to a non-zero, a timing violation will cause an interrupt and bit [{i-394}] set in the UPDATE_ERROR_STATUS parameter. FC=1
0x63C CTLPHY_WRAP__CTL_CFG__CTLCFG_DENALI_CTL_399
  [22:0] TDFI_PHYUPD_RESP_F1 — Defines the DFI tPHYUPD_RESP timing parameter [in DFI clocks], the maximum cycles between a dfi_phyupd_req assertion and a dfi_phyupd_ack assertion. If programmed to a non-zero, a timing violation will cause an interrupt and bit [5] set in the UPDATE_ERROR_STATUS parameter. FC=1
0x640 CTLPHY_WRAP__CTL_CFG__CTLCFG_DENALI_CTL_400
  [31:0] TDFI_CTRLUPD_INTERVAL_F1 — Defines the DFI tCTRLUPD_INTERVAL timing parameter [in DFI clocks], the maximum cycles between dfi_ctrlupd_req assertions. If programmed to a non-zero, a timing violation will cause an interrupt and bit [6] set in the UPDATE_ERROR_STATUS parameter. FC=1
0x644 CTLPHY_WRAP__CTL_CFG__CTLCFG_DENALI_CTL_401 reset 0x2
  [31:24] TDFI_RDDATA_EN_F1 — DFI tRDDATA_EN timing parameter. This is the number of DFI data phases between a read command and the first assertion of dfi_rddata_en_pN. FC=1
  [23:16] TDFI_RDCSLAT_F1 — Defines the DFI tPHY_RDCSLAT timing parameter [in DFI PHY clocks], the maximum cycles between a read command and a dfi_rddata_cs_n assertion. FC=1
  [10:8] TDFI_PHY_WRDATA_F1 — Defines the DFI tPHY_WRDATA timing parameter [in DFI PHY clocks], the maximum cycles between a dfi_wrdata_en assertion and a dfi_wrdata signal. FC=1
  [3:0] TDFI_CTRL_DELAY_F1 — Defines the DFI tCTRL_DELAY timing parameter [in DFI clocks], the delay between a DFI command change and a memory command. FC=1
0x648 CTLPHY_WRAP__CTL_CFG__CTLCFG_DENALI_CTL_402 reset 0x60000
  [23:16] TDFI_PHY_RDLAT_F2 — Defines the DFI tPHY_RDLAT timing parameter [in DFI PHY clocks], the maximum cycles between a dfi_rddata_en assertion and a dfi_rddata_valid assertion. FC=2
  [15:8] TDFI_PHY_WRLAT_F1 — DFI tPHY_WRLAT timing parameter. This is the number of DFI data phases between a write command and the first assertion of dfi_wrdata_en_pN. FC=1
  [7:0] TDFI_WRCSLAT_F1 — Defines the DFI tPHY_WRCSLAT timing parameter [in DFI PHY clocks], the maximum cycles between a write command and a dfi_wrdata_cs_n assertion. FC=1
0x64C CTLPHY_WRAP__CTL_CFG__CTLCFG_DENALI_CTL_403
  [20:0] TDFI_CTRLUPD_MAX_F2 — Defines the DFI tCTRLUPD_MAX timing parameter [in DFI clocks], the maximum cycles that dfi_ctrlupd_req can be asserted. If programmed to a non-zero, a timing violation will cause an interrupt and bit [0] set in the UPDATE_ERROR_STATUS parameter. FC=2
{0x0+4i} CTLPHY_WRAP__CTL_CFG__CTLCFG_DENALI_CTL_{i} (i=404..407)
  [31:0] TDFI_PHYUPD_TYPE{i-404}_F2 — Defines the DFI tPHYUPD_TYPE{i-404} timing parameter [in DFI clocks], the maximum cycles that dfi_phyupd_req can assert after dfi_phyupd_ack for dfi_phyupd_type {i-404}. If programmed to a non-zero, a timing violation will cause an interrupt and bit [{i-403}] set in the UPDATE_ERROR_STATUS parameter. FC=2
0x660 CTLPHY_WRAP__CTL_CFG__CTLCFG_DENALI_CTL_408
  [22:0] TDFI_PHYUPD_RESP_F2 — Defines the DFI tPHYUPD_RESP timing parameter [in DFI clocks], the maximum cycles between a dfi_phyupd_req assertion and a dfi_phyupd_ack assertion. If programmed to a non-zero, a timing violation will cause an interrupt and bit [5] set in the UPDATE_ERROR_STATUS parameter. FC=2
0x664 CTLPHY_WRAP__CTL_CFG__CTLCFG_DENALI_CTL_409
  [31:0] TDFI_CTRLUPD_INTERVAL_F2 — Defines the DFI tCTRLUPD_INTERVAL timing parameter [in DFI clocks], the maximum cycles between dfi_ctrlupd_req assertions. If programmed to a non-zero, a timing violation will cause an interrupt and bit [6] set in the UPDATE_ERROR_STATUS parameter. FC=2
0x668 CTLPHY_WRAP__CTL_CFG__CTLCFG_DENALI_CTL_410 reset 0x2
  [31:24] TDFI_RDDATA_EN_F2 — DFI tRDDATA_EN timing parameter. This is the number of DFI data phases between a read command and the first assertion of dfi_rddata_en_pN. FC=2
  [23:16] TDFI_RDCSLAT_F2 — Defines the DFI tPHY_RDCSLAT timing parameter [in DFI PHY clocks], the maximum cycles between a read command and a dfi_rddata_cs_n assertion. FC=2
  [10:8] TDFI_PHY_WRDATA_F2 — Defines the DFI tPHY_WRDATA timing parameter [in DFI PHY clocks], the maximum cycles between a dfi_wrdata_en assertion and a dfi_wrdata signal. FC=2
  [3:0] TDFI_CTRL_DELAY_F2 — Defines the DFI tCTRL_DELAY timing parameter [in DFI clocks], the delay between a DFI command change and a memory command. FC=2
0x66C CTLPHY_WRAP__CTL_CFG__CTLCFG_DENALI_CTL_411
  [31:16] DLL_RST_DELAY — Minimum cycles required for DLL reset signal dll_rst_n to be held. If this signal is not being used by the PHY, this parameter may be ignored.
  [15:8] TDFI_PHY_WRLAT_F2 — DFI tPHY_WRLAT timing parameter. This is the number of DFI data phases between a write command and the first assertion of dfi_wrdata_en_pN. FC=2
  [7:0] TDFI_WRCSLAT_F2 — Defines the DFI tPHY_WRCSLAT timing parameter [in DFI PHY clocks], the maximum cycles between a write command and a dfi_wrdata_cs_n assertion. FC=2
0x670 CTLPHY_WRAP__CTL_CFG__CTLCFG_DENALI_CTL_412 access per field
  [17:16] DRAM_CLK_DISABLE rw — Set value for the dfi_dram_clk_disable signal. Bit [0] controls cs0, bit [1] controls cs1, etc. Set each bit to 1 to disable.
  [14:8] UPDATE_ERROR_STATUS ro — Identifies the source of any DFI MC-initiated or PHY-initiated update errors. Value of 1 indicates a timing violation of the associated timing parameter. READ-ONLY
  [7:0] DLL_RST_ADJ_DLY rw — Minimum cycles after setting master delay in DLL until the DLL reset signal dll_rst_n may be asserted. If this signal is not being used by the PHY, this parameter may be ignored.
0x674 CTLPHY_WRAP__CTL_CFG__CTLCFG_DENALI_CTL_413
  [27:24] TDFI_DRAM_CLK_ENABLE — Defines the DFI tDRAM_CLK_ENABLE timing parameter [in DFI clocks], the delay between a dfi_dram_clk_disable de-assertion and the memory clock enable.
  [19:16] TDFI_DRAM_CLK_DISABLE — Defines the DFI tDRAM_CLK_DISABLE timing parameter [in DFI clocks], the delay between a dfi_dram_clock_disable assertion and the memory clock disable.
  [15:0] TDFI_CTRLUPD_MIN — Defines the DFI tCTRLUPD_MIN timing parameter [in DFI clocks], the minimum cycles that dfi_ctrlupd_req must be asserted.
0x678 CTLPHY_WRAP__CTL_CFG__CTLCFG_DENALI_CTL_414
  [26:24] STRATEGY_2TICK_COUNT — NEED TO FiLL IN .
  [16] DISABLE_MEMORY_MASKED_WRITE — Restricts the controller from masked write commands. Set to 1 to not issue these commands. Only used if connected to an LPDDR4 device.
  [15:8] TDFI_WRDATA_DELAY — Defines the tWRDATA_DELAY timing parameter [in DFI PHY clocks], the maximum cycles between when the dfi_wrdata_en signal is asserted and when the corresponding write data transfer is completed on the DRAM bus.
  [2:0] TDFI_PARIN_LAT — Defines the DFI tPARIN_LAT timing parameter [in DFI PHY clocks], the maximum cycles between a DFI command and a dfi_parity_in signal assertion.
0x67C CTLPHY_WRAP__CTL_CFG__CTLCFG_DENALI_CTL_415 reset 0x1010000
  [26:24] BANK_ACTIVATE_4TICK_COUNT — NEED TO FiLL IN .
  [18:16] STRATEGY_4TICK_COUNT — NEED TO FiLL IN .
  [10:8] PRE_2TICK_COUNT — NEED TO FiLL IN .
  [2:0] BANK_ACTIVATE_2TICK_COUNT — NEED TO FiLL IN .
0x680 CTLPHY_WRAP__CTL_CFG__CTLCFG_DENALI_CTL_416 reset 0x10001
  [27:24] TMP_NXN_TICK_PLUS_ADJ — NEED TO FiLL IN .
  [19:16] TMP_2X4_TICK_MINUS_ADJ — NEED TO FiLL IN .
  [11:8] TMP_2X4_TICK_PLUS_ADJ — NEED TO FiLL IN .
  [2:0] PRE_4TICK_COUNT — NEED TO FiLL IN .
0x684 CTLPHY_WRAP__CTL_CFG__CTLCFG_DENALI_CTL_417 reset 0x1010001
  [27:24] TRAS_TICK_PLUS_ADJ — NEED TO FiLL IN .
  [19:16] ODT_TICK_MINUS_ADJ — NEED TO FiLL IN .
  [11:8] ODT_TICK_PLUS_ADJ — NEED TO FiLL IN .
  [3:0] TMP_NXN_TICK_MINUS_ADJ — NEED TO FiLL IN .
0x688 CTLPHY_WRAP__CTL_CFG__CTLCFG_DENALI_CTL_418 reset 0x2000100
  [27:24] TWR_TICK_PLUS_ADJ — NEED TO FiLL IN .
  [19:16] TRP_TICK_MINUS_ADJ — NEED TO FiLL IN .
  [11:8] TRP_TICK_PLUS_ADJ — NEED TO FiLL IN .
  [3:0] TRAS_TICK_MINUS_ADJ — NEED TO FiLL IN .
0x68C CTLPHY_WRAP__CTL_CFG__CTLCFG_DENALI_CTL_419 reset 0x200
  [27:24] TRFC_TICK_PLUS_ADJ — NEED TO FiLL IN .
  [19:16] TMP_4X2_TICK_MINUS_ADJ — NEED TO FiLL IN .
  [11:8] TMP_4X2_TICK_PLUS_ADJ — NEED TO FiLL IN .
  [3:0] TWR_TICK_MINUS_ADJ — NEED TO FiLL IN .
0x690 CTLPHY_WRAP__CTL_CFG__CTLCFG_DENALI_CTL_420 reset 0x2000201
  [27:24] WL_TICK_PLUS_ADJ — NEED TO FiLL IN .
  [19:16] RL_TICK_MINUS_ADJ — NEED TO FiLL IN .
  [11:8] RL_TICK_PLUS_ADJ — NEED TO FiLL IN .
  [3:0] TRFC_TICK_MINUS_ADJ — NEED TO FiLL IN .
0x694 CTLPHY_WRAP__CTL_CFG__CTLCFG_DENALI_CTL_421 reset 0x28282800
  [31:24] NWR_F2 — DRAM NWR value in cycles. FC=2
  [23:16] NWR_F1 — DRAM NWR value in cycles. FC=1
  [15:8] NWR_F0 — DRAM NWR value in cycles. FC=0
  [3:0] WL_TICK_MINUS_ADJ — NEED TO FiLL IN .
0x698 CTLPHY_WRAP__CTL_CFG__CTLCFG_DENALI_CTL_422
  [22:16] TDFI_CTRLMSG_RESP_F2 — Defines the DFI tCTRLMSG_RESP timing parameter [in DFI clocks], the maximum number of DFI clocks allowed for dfi_ctrlmsg_ack to assert after dfi_ctrlmsg_req goes high. FC=2
  [14:8] TDFI_CTRLMSG_RESP_F1 — Defines the DFI tCTRLMSG_RESP timing parameter [in DFI clocks], the maximum number of DFI clocks allowed for dfi_ctrlmsg_ack to assert after dfi_ctrlmsg_req goes high. FC=1
  [6:0] TDFI_CTRLMSG_RESP_F0 — Defines the DFI tCTRLMSG_RESP timing parameter [in DFI clocks], the maximum number of DFI clocks allowed for dfi_ctrlmsg_ack to assert after dfi_ctrlmsg_req goes high. FC=0
